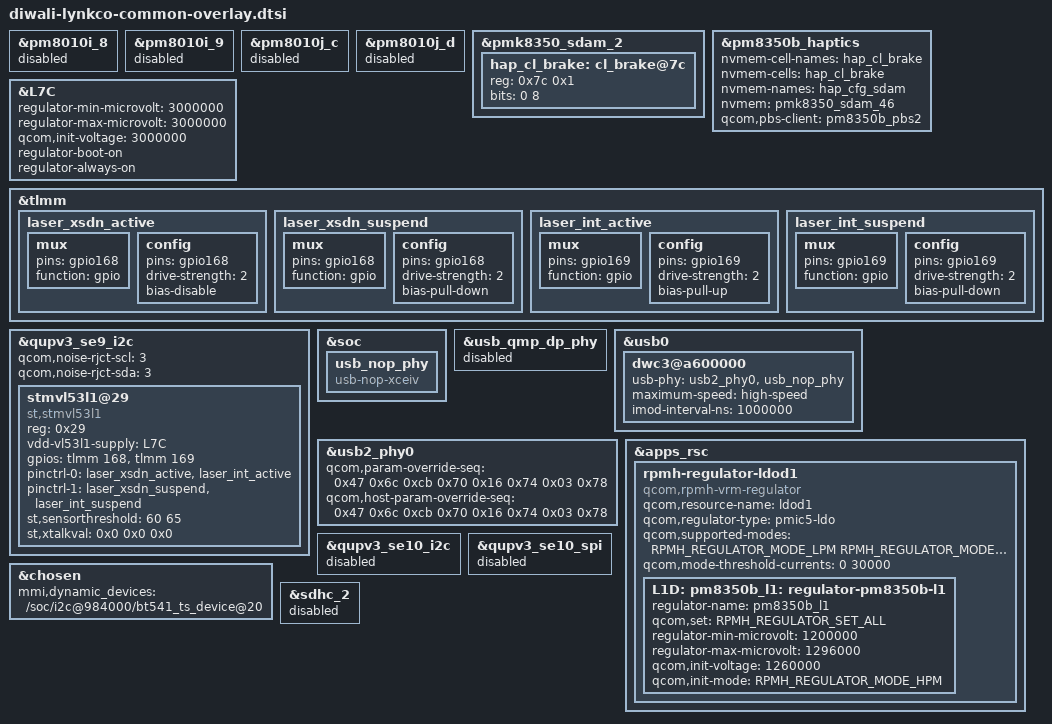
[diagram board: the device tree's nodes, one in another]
/* Copyright (c) 2022, The Linux Foundation. All rights reserved.
 *
 * This program is free software; you can redistribute it and/or modify
 * it under the terms of the GNU General Public License version 2 and
 * only version 2 as published by the Free Software Foundation.
 *
 * This program is distributed in the hope that it will be useful,
 * but WITHOUT ANY WARRANTY; without even the implied warranty of
 * MERCHANTABILITY or FITNESS FOR A PARTICULAR PURPOSE.  See the
 * GNU General Public License for more details.
 */

/*
   This base is original from "diwali-qrd-overlay.dts"
*/

#include <dt-bindings/interconnect/qcom,diwali.h>

#include "diwali-moto-common-overlay-base.dtsi"
#include "diwali-moto-pm8350b.dtsi"
#include "diwali-moto-common-overlay.dtsi"
#include "diwali-lynkco-touchscreen-overlay.dtsi"
#include "moto-lynkco-wl2864c.dtsi"
#include "diwali-lynkco-haptics-overlay.dtsi"
#include "diwali-lynkco-fingerprint-overlay.dtsi"
#include "diwali-moto-common-charger.dtsi"
#include "diwali-lynkco-charger-overlay.dtsi"
#include <dt-bindings/regulator/qcom,rpmh-regulator-levels.h>
#include "diwali-moto-qca6490-overlay.dtsi"
#include "diwali-lynkco-nfc-overlay.dtsi"
#include "diwali-lynkco-thermal-overlay.dtsi"

&pm8010i_8 {
	status = "disabled";
};

&pm8010i_9 {
	status = "disabled";
};

&pm8010j_c {
	status = "disabled";
};

&pm8010j_d {
	status = "disabled";
};

&pmk8350_sdam_2 {
	hap_cl_brake: cl_brake@7c {
		reg = <0x7c 0x1>;
		bits = <0 8>;
	};
};

&pm8350b_haptics {
	nvmem-cell-names = "hap_cl_brake";
	nvmem-cells = <&hap_cl_brake>;
	nvmem-names = "hap_cfg_sdam";
	nvmem = <&pmk8350_sdam_46>;
	qcom,pbs-client = <&pm8350b_pbs2>;
};

&L7C {
	regulator-min-microvolt = <3000000>;
	regulator-max-microvolt = <3000000>;
	qcom,init-voltage = <3000000>;
	regulator-boot-on;
	regulator-always-on;
};

&tlmm {
        laser_xsdn_active: laser_xsdn_active {
		mux {
			pins = "gpio168";
			function = "gpio";
		};

		config {
			pins = "gpio168";
			drive-strength = <2>;
			bias-disable;
		};
	};

	laser_xsdn_suspend: laser_xsdn_suspend {
		mux {
			pins = "gpio168";
			function = "gpio";
		};

		config {
			pins = "gpio168";
			drive-strength = <2>;
			bias-pull-down; /* PULL DOWN */
		};
	};

	laser_int_active: laser_int_active {
		mux {
			pins = "gpio169";
			function = "gpio";
		};

		config {
			pins = "gpio169";
			drive-strength = <2>;
			bias-pull-up; /* PULL UP */
		};
	};

	laser_int_suspend: laser_int_suspend {
		mux {
			pins = "gpio169";
			function = "gpio";
		};

		config {
			pins = "gpio169";
			drive-strength = <2>;
			bias-pull-down; /* PULL DOWN */
		};
	};
};

&qupv3_se9_i2c {
	status = "okay";
	qcom,noise-rjct-scl = <3>;
	qcom,noise-rjct-sda = <3>;
	stmvl53l1@29 {
		status = "ok";
		compatible = "st,stmvl53l1";
		reg = <0x29>;
		vdd-vl53l1-supply = <&L7C>;
		gpios = <&tlmm 168 0>, <&tlmm 169 0>;
		pinctrl-names = "laser_default", "laser_suspend";
		pinctrl-0 = <&laser_xsdn_active &laser_int_active>;
		pinctrl-1 = <&laser_xsdn_suspend &laser_int_suspend>;
		st,sensorthreshold = <60 65>;
		st,xtalkval = <0x0 0x0 0x0>;
	};
};

&soc {
	usb_nop_phy: usb_nop_phy {
		compatible = "usb-nop-xceiv";
	};
};

&usb_qmp_dp_phy {
	status = "disabled";
};

&usb0 {
	dwc3@a600000 {
		usb-phy = <&usb2_phy0>, <&usb_nop_phy>;
		maximum-speed = "high-speed";
		imod-interval-ns = <1000000>;
	};
};

&usb2_phy0 {
	qcom,param-override-seq = <
			/* override x0 */
			0x47 0x6c
			/* override x1 */
			0xcb 0x70
			/* override x2 */
			0x16 0x74
			/* override x3 */
			0x03 0x78>;
	qcom,host-param-override-seq = <
			/* override x0 */
			0x47 0x6c
			/* override x1 */
			0xcb 0x70
			/* override x2 */
			0x16 0x74
			/* override x3 */
			0x03 0x78>;
};

&apps_rsc {
	rpmh-regulator-ldod1 {
		compatible = "qcom,rpmh-vrm-regulator";
		qcom,resource-name = "ldod1";
		qcom,regulator-type = "pmic5-ldo";
		qcom,supported-modes =
			<RPMH_REGULATOR_MODE_LPM
			 RPMH_REGULATOR_MODE_HPM>;
		qcom,mode-threshold-currents = <0 30000>;
		L1D: pm8350b_l1: regulator-pm8350b-l1 {
			regulator-name = "pm8350b_l1";
			qcom,set = <RPMH_REGULATOR_SET_ALL>;
			regulator-min-microvolt = <1200000>;
			regulator-max-microvolt = <1296000>;
			qcom,init-voltage = <1260000>;
			qcom,init-mode = <RPMH_REGULATOR_MODE_HPM>;
		};
	};
};

&qupv3_se10_i2c {
       status = "disabled";
};

&qupv3_se10_spi {
       status = "disabled";
};

&chosen {
    mmi,dynamic_devices = "/soc/i2c@984000/bt541_ts_device@20";
};

&sdhc_2 {
	status = "disabled";
};
